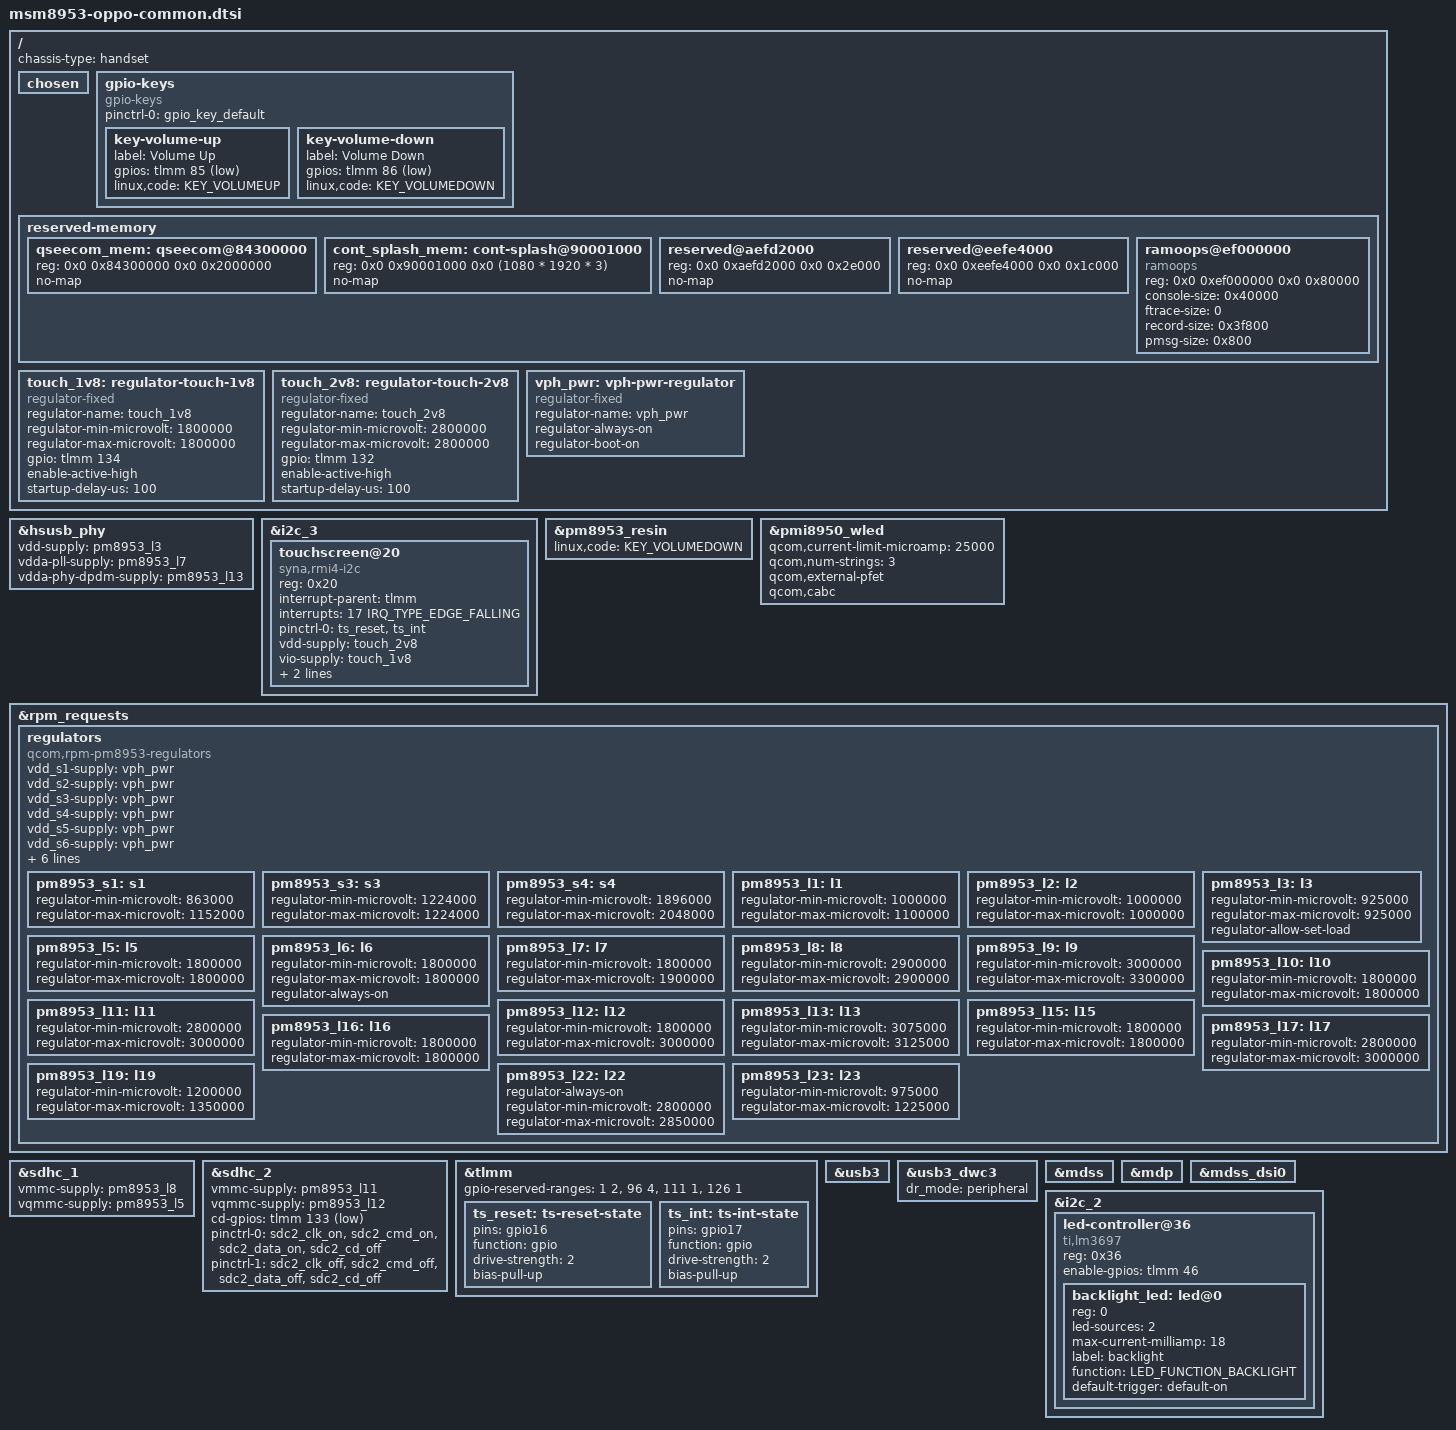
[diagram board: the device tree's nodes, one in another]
// SPDX-License-Identifier: BSD-3-Clause
/*
 * OPPO R9s / R9sk (MSM8953) —— mainline 6.12 公共部分
 *
 * 以 arch/arm64/boot/dts/qcom/msm8953-motorola-potter.dts 为蓝本改写。
 * 选 potter 做参考的原因：它和 R9s 是同一套芯片组合
 *   MSM8953 + PM8953 + PMI8950
 * 触摸屏也都挂在 i2c_3 的 0x20 上（Synaptics），所以绝大多数节点
 * 可以 1:1 照搬，只需要改机型标识、中断/复位 GPIO 和 board-id。
 *
 * 真机参数来源：本仓库 4.19 分支
 *   arch/arm64/boot/dts/vendor/qcom/oppo-msm8953/
 *     msm8953-mtp.dtsi / 16017/ / 16027/
 *
 * ⚠ 现状说明：这是 mainline 意义上的"能启动的 Linux"，
 *   不是 Android/LOS 内核。缺少的 vendor 栈见 6.12-test 分支的 README。
 */

#include <dt-bindings/leds/common.h>
#include "msm8953.dtsi"
#include "pm8953.dtsi"
#include "pmi8950.dtsi"

/*
 * mainline 的 msm8953.dtsi 带 cont_splash_mem 与 qseecom_mem 两个
 * reserved-memory 节点，但地址是按其他机型给的。这里删掉，改由本文件
 * 按 R9s 的实际布局重新声明。
 */
/delete-node/ &cont_splash_mem;
/delete-node/ &qseecom_mem;

/ {
	chassis-type = "handset";

	chosen {
		#address-cells = <2>;
		#size-cells = <2>;
		ranges;

		/*
		 * 原来这里是 simple-framebuffer（simpledrm 直接映射 bootloader
		 * 留下的连续 framebuffer）。现在改成真正的 MDSS/DSI 链路：
		 * 面板由 oppo,r63452-cmd / oppo,ea8064-cmd 两个 DRM panel 驱动接管。
		 *
		 * 这里刻意不再声明 framebuffer 节点 —— simpledrm 和 mdss 同时
		 * 拥有同一块屏幕会打架（一个写线性 framebuffer、一个配 MDP/DSI），
		 * 结果是花屏。
		 *
		 * 想回退到 simpledrm 做对照实验时，把原来的 framebuffer@90001000
		 * 节点加回来、并把下面 &mdss/&mdp/&mdss_dsi0 的 status 设回 disabled。
		 */
	};

	/*
	 * 音量键。GPIO 号取自 4.19 分支
	 * oppo-msm8953/msm8953-mtp.dtsi 的 gpio_keys 节点。
	 * 电源键走 pm8953_resin（见文件末尾）。
	 */
	gpio-keys {
		compatible = "gpio-keys";

		pinctrl-names = "default";
		pinctrl-0 = <&gpio_key_default>;

		key-volume-up {
			label = "Volume Up";
			gpios = <&tlmm 85 GPIO_ACTIVE_LOW>;
			linux,code = <KEY_VOLUMEUP>;
		};

		key-volume-down {
			label = "Volume Down";
			gpios = <&tlmm 86 GPIO_ACTIVE_LOW>;
			linux,code = <KEY_VOLUMEDOWN>;
		};
	};

	reserved-memory {
		/*
		 * 0x84300000 起 32MB：TZ/secure app 区。
		 * 4.19 分支里 OPPO 把 other_ext_mem 放在 0x84a00000，
		 * 但 mainline 用 qseecom 整块保护更保守，先按 potter 的取法。
		 */
		qseecom_mem: qseecom@84300000 {
			reg = <0x0 0x84300000 0x0 0x2000000>;
			no-map;
		};

		/* bootloader 交接的 framebuffer，标记为不可回收 */
		cont_splash_mem: cont-splash@90001000 {
			reg = <0x0 0x90001000 0x0 (1080 * 1920 * 3)>;
			no-map;
		};

		reserved@aefd2000 {
			reg = <0x0 0xaefd2000 0x0 0x2e000>;
			no-map;
		};

		reserved@eefe4000 {
			reg = <0x0 0xeefe4000 0x0 0x1c000>;
			no-map;
		};

		ramoops@ef000000 {
			compatible = "ramoops";
			reg = <0x0 0xef000000 0x0 0x80000>;
			console-size = <0x40000>;
			ftrace-size = <0>;
			record-size = <0x3f800>;
			pmsg-size = <0x800>;
		};
	};

	/*
	 * 触摸屏的两路使能（对应 vendor 的 enable1v8 / enable2v8 gpio）。
	 * 用 gpio 控制的 fixed regulator 表达，让 rmi4 驱动按标准
	 * vdd-supply / vio-supply 去 enable。
	 */
	touch_1v8: regulator-touch-1v8 {
		compatible = "regulator-fixed";
		regulator-name = "touch_1v8";
		regulator-min-microvolt = <1800000>;
		regulator-max-microvolt = <1800000>;
		gpio = <&tlmm 134 GPIO_ACTIVE_HIGH>;
		enable-active-high;
		startup-delay-us = <100>;
	};

	touch_2v8: regulator-touch-2v8 {
		compatible = "regulator-fixed";
		regulator-name = "touch_2v8";
		regulator-min-microvolt = <2800000>;
		regulator-max-microvolt = <2800000>;
		gpio = <&tlmm 132 GPIO_ACTIVE_HIGH>;
		enable-active-high;
		startup-delay-us = <100>;
	};

	vph_pwr: vph-pwr-regulator {
		compatible = "regulator-fixed";
		regulator-name = "vph_pwr";
		regulator-always-on;
		regulator-boot-on;
	};
};

&hsusb_phy {
	vdd-supply = <&pm8953_l3>;
	vdda-pll-supply = <&pm8953_l7>;
	vdda-phy-dpdm-supply = <&pm8953_l13>;

	status = "okay";
};

/*
 * 触摸屏：Synaptics，i2c_3 0x20，中断 gpio17、复位 gpio16。
 * （potter 是中断 65 / 复位 64，R9s 不同，见 4.19 的
 *   oppo-msm8953/msm8953-mtp.dtsi 与 msm8953-pinctrl.dtsi:387）
 *
 * 注意：4.19 原厂驱动是 synaptics-s3320 私有驱动，mainline 这边只能
 * 先挂通用 rmi4。S3320 是否走标准 RMI4 协议需要真机确认；若不兼容，
 * 触摸会是这台机器上第一个要补 vendor 驱动的地方。
 */
&i2c_3 {
	status = "okay";

	/*
	 * 触摸屏：Synaptics（16027 是 S3320，16 引脚 reset / 17 引脚 irq）。
	 *
	 * 4.19 vendor 驱动是私有的 synaptics-s3320，mainline 这边只能挂通用
	 * rmi4。S3320 是否走标准 RMI4 协议需要真机确认 —— 这是第一个
	 * 上机时要看的点。
	 *
	 * 供电（来自 4.19 oppo-msm8953/msm8953-mtp.dtsi 的 s3320 节点）：
	 *   synaptics,enable1v8-gpio = <&tlmm 134>   1.8V IO 使能
	 *   synaptics,enable2v8-gpio = <&tlmm 132>   2.8V 模拟使能
	 * 这两脚在 mainline 没有对应绑定，用 fixed-regulator + gpio 表达，
	 * 见下面 touch_1v8 / touch_2v8。
	 */
	touchscreen@20 {
		reg = <0x20>;
		compatible = "syna,rmi4-i2c";

		interrupt-parent = <&tlmm>;
		interrupts = <17 IRQ_TYPE_EDGE_FALLING>;

		pinctrl-names = "default";
		pinctrl-0 = <&ts_reset &ts_int>;

		vdd-supply = <&touch_2v8>;
		vio-supply = <&touch_1v8>;

		syna,reset-delay-ms = <200>;
		syna,startup-delay-ms = <500>;
	};
};

&pm8953_resin {
	linux,code = <KEY_VOLUMEDOWN>;
	status = "okay";
};

/* 背光：PMI8950 WLED，参数照抄 potter（同 PMIC、同 3 串） */
&pmi8950_wled {
	qcom,current-limit-microamp = <25000>;
	qcom,num-strings = <3>;
	qcom,external-pfet;
	qcom,cabc;

	status = "okay";
};

&rpm_requests {
	regulators {
		compatible = "qcom,rpm-pm8953-regulators";
		vdd_s1-supply = <&vph_pwr>;
		vdd_s2-supply = <&vph_pwr>;
		vdd_s3-supply = <&vph_pwr>;
		vdd_s4-supply = <&vph_pwr>;
		vdd_s5-supply = <&vph_pwr>;
		vdd_s6-supply = <&vph_pwr>;
		vdd_s7-supply = <&vph_pwr>;
		vdd_l1-supply = <&pm8953_s3>;
		vdd_l2_l3-supply = <&pm8953_s3>;
		vdd_l4_l5_l6_l7_l16_l19-supply = <&pm8953_s4>;
		vdd_l8_l11_l12_l13_l14_l15-supply = <&vph_pwr>;
		vdd_l9_l10_l17_l18_l22-supply = <&vph_pwr>;

		pm8953_s1: s1 {
			regulator-min-microvolt = <863000>;
			regulator-max-microvolt = <1152000>;
		};

		pm8953_s3: s3 {
			regulator-min-microvolt = <1224000>;
			regulator-max-microvolt = <1224000>;
		};

		pm8953_s4: s4 {
			regulator-min-microvolt = <1896000>;
			regulator-max-microvolt = <2048000>;
		};

		pm8953_l1: l1 {
			regulator-min-microvolt = <1000000>;
			regulator-max-microvolt = <1100000>;
		};

		pm8953_l2: l2 {
			regulator-min-microvolt = <1000000>;
			regulator-max-microvolt = <1000000>;
		};

		pm8953_l3: l3 {
			regulator-min-microvolt = <925000>;
			regulator-max-microvolt = <925000>;
			regulator-allow-set-load;
		};

		pm8953_l5: l5 {
			regulator-min-microvolt = <1800000>;
			regulator-max-microvolt = <1800000>;
		};

		pm8953_l6: l6 {
			regulator-min-microvolt = <1800000>;
			regulator-max-microvolt = <1800000>;
			regulator-always-on;
		};

		pm8953_l7: l7 {
			regulator-min-microvolt = <1800000>;
			regulator-max-microvolt = <1900000>;
		};

		pm8953_l8: l8 {
			regulator-min-microvolt = <2900000>;
			regulator-max-microvolt = <2900000>;
		};

		pm8953_l9: l9 {
			regulator-min-microvolt = <3000000>;
			regulator-max-microvolt = <3300000>;
		};

		pm8953_l10: l10 {
			regulator-min-microvolt = <1800000>;
			regulator-max-microvolt = <1800000>;
		};

		pm8953_l11: l11 {
			regulator-min-microvolt = <2800000>;
			regulator-max-microvolt = <3000000>;
		};

		pm8953_l12: l12 {
			regulator-min-microvolt = <1800000>;
			regulator-max-microvolt = <3000000>;
		};

		pm8953_l13: l13 {
			regulator-min-microvolt = <3075000>;
			regulator-max-microvolt = <3125000>;
		};

		pm8953_l15: l15 {
			regulator-min-microvolt = <1800000>;
			regulator-max-microvolt = <1800000>;
		};

		pm8953_l16: l16 {
			regulator-min-microvolt = <1800000>;
			regulator-max-microvolt = <1800000>;
		};

		pm8953_l17: l17 {
			regulator-min-microvolt = <2800000>;
			regulator-max-microvolt = <3000000>;
		};

		pm8953_l19: l19 {
			regulator-min-microvolt = <1200000>;
			regulator-max-microvolt = <1350000>;
		};

		pm8953_l22: l22 {
			regulator-always-on;
			regulator-min-microvolt = <2800000>;
			regulator-max-microvolt = <2850000>;
		};

		pm8953_l23: l23 {
			regulator-min-microvolt = <975000>;
			regulator-max-microvolt = <1225000>;
		};
	};
};

/* eMMC */
&sdhc_1 {
	vmmc-supply = <&pm8953_l8>;
	vqmmc-supply = <&pm8953_l5>;

	status = "okay";
};

/*
 * SD 卡槽。
 * 卡检测用 GPIO 133（与 potter 相同；4.19 的 R9s 也是这个脚，
 * 另外还有一个 sdcard_vdd_enable 电源使能脚，但 mainline 的
 * sdhci-msm 没有对应属性，暂不处理 —— SD 卡是否真能识别需要真机验证）。
 */
&sdhc_2 {
	vmmc-supply = <&pm8953_l11>;
	vqmmc-supply = <&pm8953_l12>;

	cd-gpios = <&tlmm 133 GPIO_ACTIVE_LOW>;

	pinctrl-names = "default", "sleep";
	pinctrl-0 = <&sdc2_clk_on &sdc2_cmd_on &sdc2_data_on &sdc2_cd_off>;
	pinctrl-1 = <&sdc2_clk_off &sdc2_cmd_off &sdc2_data_off &sdc2_cd_off>;

	status = "okay";
};

&tlmm {
	/*
	 * 保留引脚：这几个被 bootloader / TZ 占着，Linux 不能碰。
	 * 具体范围沿用 potter，R9s 上如果出现 gpio 申请失败再逐条核对。
	 */
	gpio-reserved-ranges = <1 2>, <96 4>, <111 1>, <126 1>;

	/* 触摸屏复位脚 gpio16（4.19: msm8953-pinctrl.dtsi 的 ts_reset_active） */
	ts_reset: ts-reset-state {
		pins = "gpio16";
		function = "gpio";
		drive-strength = <2>;
		bias-pull-up;
	};

	/* 触摸屏中断脚 gpio17（4.19: ts_int_active） */
	ts_int: ts-int-state {
		pins = "gpio17";
		function = "gpio";
		drive-strength = <2>;
		bias-pull-up;
	};
};

&usb3 {
	status = "okay";
};

&usb3_dwc3 {
	/delete-property/ usb-role-switch;
	dr_mode = "peripheral";
};

/*
 * 显示链路：MDSS + MDP5 + DSI0 + 面板。
 *
 * msm8953.dtsi 里这些节点都是现成的（mdss/mdp/mdss_dsi0/mdss_dsi0_phy，
 * DSI 控制器 compatible 是 qcom,msm8953-dsi-ctrl），主线 drm/msm 的
 * MDP5 + DSI 驱动可以直接用。
 */
&mdss {
	status = "okay";
};

&mdp {
	status = "okay";
};

&mdss_dsi0 {
	status = "okay";

	/*
	 * 具体面板节点放在各机型 dts 里（r9s 是 EA8064，r9sk 是 R63452），
	 * 因为它们 compatile 不同。
	 */
};

/*
 * 背光：TI LM3697 @ i2c_2 0x36，enable GPIO 46
 *
 * 参数来自本仓库 4.19 的 oppo-msm8953/16027/msm8953-mtp.dtsi：
 *     lm3697@36 {
 *         ti,enable-gpio = <&tlmm 46 0x00>;
 *         lcd_bl { led-sources = <2>; max-current-milliamp = <18>;
 *                  initial-brightness = <1024>; };
 *     };
 *
 * 换算到主线 leds-lm3697 绑定：
 *   · 主线的 enable 属性名是 enable-gpios（devm_gpiod_get(dev, "enable")）
 *   · 主线的子节点用 reg 表示 control bank（只能是 0/1，对应 CONTROL_A/B），
 *     而 vendor 的 led-sources=<2> 才是"用第 3 路灯串"的意思 ——
 *     两者含义不同，别把 2 写进 reg，否则 probe 直接报 "reg property is invalid"
 *   · vled-supply 不写也行：devm_regulator_get() 拿不到 supply 时
 *     会退化成 dummy regulator
 *
 * default-trigger 用 "default-on"：bring-up 阶段没有 Android 用户态去设
 * 亮度，用这个触发器可以在内核启动时就把背光点亮（最亮），
 * 好让"屏到底亮没亮"这件事可观测。
 * 将来接 Android 时改成 led-backlight 桥接（CONFIG_BACKLIGHT_LED），
 * 由 HAL 通过 /sys/class/backlight 控制。
 */
&i2c_2 {
	status = "okay";

	led-controller@36 {
		compatible = "ti,lm3697";
		reg = <0x36>;

		enable-gpios = <&tlmm 46 GPIO_ACTIVE_HIGH>;

		#address-cells = <1>;
		#size-cells = <0>;

		backlight_led: led@0 {
			reg = <0>;
			led-sources = <2>;
			max-current-milliamp = <18>;
			label = "backlight";
			function = LED_FUNCTION_BACKLIGHT;
			default-trigger = "default-on";
		};
	};
};
